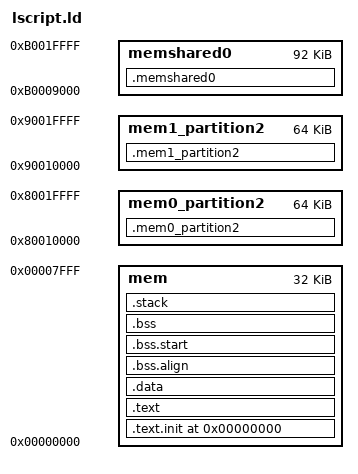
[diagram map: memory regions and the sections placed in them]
/* DO NOT EDIT
 * this file was automatically generated by ../../tools/generate-json from ../vep-config.txt for
 * VEP_ID=1 TILE_ID=0 PARTITION_ID=1
 */

MEMORY {
mem : ORIGIN = 0x0, LENGTH = 0x00008000 /* remove shared partition region, starting after the stack at LENGTH */
mem0_partition2 : ORIGIN = 0x80010000, LENGTH = 0x00010000 /* vep=1 tile=0 partition=2 private shared memory region */
mem1_partition2 : ORIGIN = 0x90010000, LENGTH = 0x00010000 /* vep=1 tile=1 partition=2 private shared memory region */
memshared0 : ORIGIN = 0xB0009000, LENGTH = 0x00017000 /* vep=1 private shared memory region */
}
_STACK_SIZE = 0x00004000;
OUTPUT_ARCH( "riscv" )
ENTRY( _start )
_STACK_SIZE = DEFINED(_STACK_SIZE) ? _STACK_SIZE : 0x1000;
SECTIONS
{
  . = 0x00000000;
  .text.init : { *(.text.init) } > mem
  .text : { *(.text) } > mem
  .data : { *(.data) } > mem
  .bss.align :
   {
           . = ALIGN(4);
           _bss = .;
   } > mem
   .bss.start :
   {
          _bss_lma = LOADADDR(.bss.start);
   } >mem
   .bss :
   {
           *(.sbss*)
           *(.gnu.linkonce.sb.*)
           *(.bss .bss.*)
           *(.gnu.linkonce.b.*)
           *(COMMON)
        . = ALIGN(4);
        _ebss = .;
   } >mem
  .mem0_partition2 : { *(.mem0_partition2) } > mem0_partition2
  .mem1_partition2 : { *(.mem1_partition2) } > mem1_partition2
  .memshared0 : { *(.memshared0) } > memshared0
  _end = .;
  .stack (NOLOAD) : {
          _stack_end = .;
          . += _STACK_SIZE;
          . = ALIGN(16);
          _stack_start = .;
  } > mem
  PROVIDE (end = .);
}
